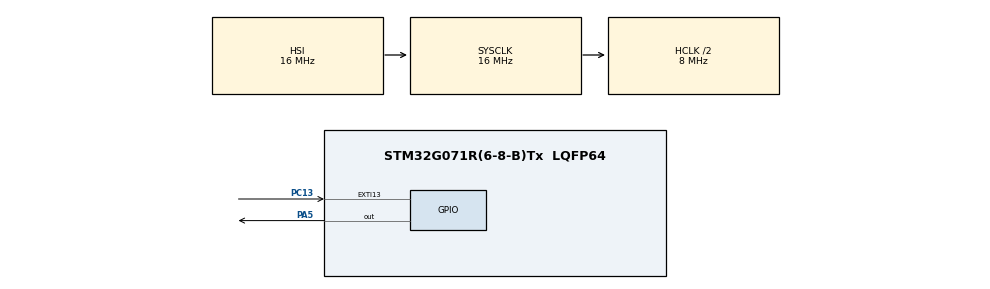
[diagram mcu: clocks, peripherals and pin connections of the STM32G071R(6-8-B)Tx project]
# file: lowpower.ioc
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Mcu.Family=STM32G0
Mcu.Name=STM32G071R(6-8-B)Tx
Mcu.Package=LQFP64
NVIC.EXTI4_15_IRQn=true\:0\:0\:false\:false\:true\:true
NVIC.RTC_TAMP_IRQn=true\:0\:0\:false\:false\:true\:true
PA5.Signal=GPIO_Output
PC13.Signal=GPXTI13
PC14-OSC32_IN\ (PC14).Mode=LSE-External-Oscillator
PC14-OSC32_IN\ (PC14).Signal=RCC_OSC32_IN
PC15-OSC32_OUT\ (PC15).Mode=LSE-External-Oscillator
PC15-OSC32_OUT\ (PC15).Signal=RCC_OSC32_OUT
ProjectManager.HeapSize=0x200
ProjectManager.StackSize=0x400
ProjectManager.TargetToolchain=MDK-ARM V5
RCC.AHBCLKDivider=RCC_SYSCLK_DIV2
RCC.AHBFreq_Value=8000000
RCC.CortexFreq_Value=8000000
RCC.EXTERNAL_CLOCK_VALUE=48000
RCC.HCLKFreq_Value=8000000
RCC.HSE_VALUE=8000000
RCC.HSI_VALUE=16000000
RCC.RTCClockSelection=RCC_RTCCLKSOURCE_LSE
RCC.SYSCLKFreq_VALUE=16000000
RCC.VCOOutputFreq_Value=128000000
RTC.WakeUpCounter-WakeUp=10246
VP_RTC_VS_RTC_Activate.Mode=RTC_Enabled
VP_RTC_VS_RTC_WakeUp_intern.Mode=WakeUp
board=custom

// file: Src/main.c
/* USER CODE BEGIN Header */
/**
  ******************************************************************************
  * @file           : main.c
  * @brief          : Main program body
  ******************************************************************************
  ** This notice applies to any and all portions of this file
  * that are not between comment pairs USER CODE BEGIN and
  * USER CODE END. Other portions of this file, whether
  * inserted by the user or by software development tools
  * are owned by their respective copyright owners.
  *
  * COPYRIGHT(c) 2019 STMicroelectronics
  *
  * Redistribution and use in source and binary forms, with or without modification,
  * are permitted provided that the following conditions are met:
  *   1. Redistributions of source code must retain the above copyright notice,
  *      this list of conditions and the following disclaimer.
  *   2. Redistributions in binary form must reproduce the above copyright notice,
  *      this list of conditions and the following disclaimer in the documentation
  *      and/or other materials provided with the distribution.
  *   3. Neither the name of STMicroelectronics nor the names of its contributors
  *      may be used to endorse or promote products derived from this software
  *      without specific prior written permission.
  *
  * THIS SOFTWARE IS PROVIDED BY THE COPYRIGHT HOLDERS AND CONTRIBUTORS "AS IS"
  * AND ANY EXPRESS OR IMPLIED WARRANTIES, INCLUDING, BUT NOT LIMITED TO, THE
  * IMPLIED WARRANTIES OF MERCHANTABILITY AND FITNESS FOR A PARTICULAR PURPOSE ARE
  * DISCLAIMED. IN NO EVENT SHALL THE COPYRIGHT HOLDER OR CONTRIBUTORS BE LIABLE
  * FOR ANY DIRECT, INDIRECT, INCIDENTAL, SPECIAL, EXEMPLARY, OR CONSEQUENTIAL
  * DAMAGES (INCLUDING, BUT NOT LIMITED TO, PROCUREMENT OF SUBSTITUTE GOODS OR
  * SERVICES; LOSS OF USE, DATA, OR PROFITS; OR BUSINESS INTERRUPTION) HOWEVER
  * CAUSED AND ON ANY THEORY OF LIABILITY, WHETHER IN CONTRACT, STRICT LIABILITY,
  * OR TORT (INCLUDING NEGLIGENCE OR OTHERWISE) ARISING IN ANY WAY OUT OF THE USE
  * OF THIS SOFTWARE, EVEN IF ADVISED OF THE POSSIBILITY OF SUCH DAMAGE.
  *
  ******************************************************************************
  */
/* USER CODE END Header */

#include "main.h"

RTC_HandleTypeDef hrtc;

void SystemClock_Config(void);
static void MX_GPIO_Init(void);
static void MX_RTC_Init(void);

int main(void)
{

  /* MCU Configuration--------------------------------------------------------*/

  /* Reset of all peripherals, Initializes the Flash interface and the Systick. */
  HAL_Init();

  /* Configure the system clock */
  SystemClock_Config();

  /* Initialize all configured peripherals */
  MX_GPIO_Init();
  MX_RTC_Init();

  /* Infinite loop */
  /* USER CODE BEGIN WHILE */
  while (1)
  {
		HAL_GPIO_WritePin(GPIOA, GPIO_PIN_5, GPIO_PIN_SET);
		HAL_Delay(1000);
		HAL_GPIO_WritePin(GPIOA, GPIO_PIN_5, GPIO_PIN_RESET);

		// enter STOP mode
		HAL_PWR_EnterSTOPMode(PWR_LOWPOWERREGULATOR_ON, PWR_STOPENTRY_WFI);

		// reconfigure system clock
		SystemClock_Config();
    /* USER CODE END WHILE */

  }
}

void SystemClock_Config(void)
{
  RCC_OscInitTypeDef RCC_OscInitStruct = {0};
  RCC_ClkInitTypeDef RCC_ClkInitStruct = {0};
  RCC_PeriphCLKInitTypeDef PeriphClkInit = {0};

  /**Configure the main internal regulator output voltage
  */
  HAL_PWREx_ControlVoltageScaling(PWR_REGULATOR_VOLTAGE_SCALE1);
  /**Configure LSE Drive Capability
  */
  __HAL_RCC_LSEDRIVE_CONFIG(RCC_LSEDRIVE_LOW);
  /**Initializes the CPU, AHB and APB busses clocks
  */
  RCC_OscInitStruct.OscillatorType = RCC_OSCILLATORTYPE_HSI|RCC_OSCILLATORTYPE_LSE;
  RCC_OscInitStruct.LSEState = RCC_LSE_ON;
  RCC_OscInitStruct.HSIState = RCC_HSI_ON;
  RCC_OscInitStruct.HSIDiv = RCC_HSI_DIV1;
  RCC_OscInitStruct.HSICalibrationValue = RCC_HSICALIBRATION_DEFAULT;
  RCC_OscInitStruct.PLL.PLLState = RCC_PLL_NONE;
  if (HAL_RCC_OscConfig(&RCC_OscInitStruct) != HAL_OK)
  {
    Error_Handler();
  }
  /**Initializes the CPU, AHB and APB busses clocks
  */
  RCC_ClkInitStruct.ClockType = RCC_CLOCKTYPE_HCLK|RCC_CLOCKTYPE_SYSCLK
                              |RCC_CLOCKTYPE_PCLK1;
  RCC_ClkInitStruct.SYSCLKSource = RCC_SYSCLKSOURCE_HSI;
  RCC_ClkInitStruct.AHBCLKDivider = RCC_SYSCLK_DIV2;
  RCC_ClkInitStruct.APB1CLKDivider = RCC_HCLK_DIV1;

  if (HAL_RCC_ClockConfig(&RCC_ClkInitStruct, FLASH_LATENCY_0) != HAL_OK)
  {
    Error_Handler();
  }
  /**Initializes the peripherals clocks
  */
  PeriphClkInit.PeriphClockSelection = RCC_PERIPHCLK_RTC;
  PeriphClkInit.RTCClockSelection = RCC_RTCCLKSOURCE_LSE;

  if (HAL_RCCEx_PeriphCLKConfig(&PeriphClkInit) != HAL_OK)
  {
    Error_Handler();
  }
}

static void MX_RTC_Init(void)
{

  /**Initialize RTC Only
  */
  hrtc.Instance = RTC;
  hrtc.Init.HourFormat = RTC_HOURFORMAT_24;
  hrtc.Init.AsynchPrediv = 127;
  hrtc.Init.SynchPrediv = 255;
  hrtc.Init.OutPut = RTC_OUTPUT_DISABLE;
  hrtc.Init.OutPutRemap = RTC_OUTPUT_REMAP_NONE;
  hrtc.Init.OutPutPolarity = RTC_OUTPUT_POLARITY_HIGH;
  hrtc.Init.OutPutType = RTC_OUTPUT_TYPE_OPENDRAIN;
  hrtc.Init.OutPutPullUp = RTC_OUTPUT_PULLUP_NONE;
  if (HAL_RTC_Init(&hrtc) != HAL_OK)
  {
    Error_Handler();
  }
  /**Enable the WakeUp
  */
  if (HAL_RTCEx_SetWakeUpTimer_IT(&hrtc, 10246, RTC_WAKEUPCLOCK_RTCCLK_DIV16) != HAL_OK)
  {
    Error_Handler();
  }

}

static void MX_GPIO_Init(void)
{
  GPIO_InitTypeDef GPIO_InitStruct = {0};

  /* GPIO Ports Clock Enable */
  __HAL_RCC_GPIOC_CLK_ENABLE();
  __HAL_RCC_GPIOA_CLK_ENABLE();

  /*Configure GPIO pin Output Level */
  HAL_GPIO_WritePin(GPIOA, GPIO_PIN_5, GPIO_PIN_RESET);

  /*Configure GPIO pin : PC13 */
  GPIO_InitStruct.Pin = GPIO_PIN_13;
  GPIO_InitStruct.Mode = GPIO_MODE_IT_RISING;
  GPIO_InitStruct.Pull = GPIO_NOPULL;
  HAL_GPIO_Init(GPIOC, &GPIO_InitStruct);

  /*Configure GPIO pin : PA5 */
  GPIO_InitStruct.Pin = GPIO_PIN_5;
  GPIO_InitStruct.Mode = GPIO_MODE_OUTPUT_PP;
  GPIO_InitStruct.Pull = GPIO_NOPULL;
  GPIO_InitStruct.Speed = GPIO_SPEED_FREQ_LOW;
  HAL_GPIO_Init(GPIOA, &GPIO_InitStruct);

  /* EXTI interrupt init*/
  HAL_NVIC_SetPriority(EXTI4_15_IRQn, 0, 0);
  HAL_NVIC_EnableIRQ(EXTI4_15_IRQn);

}

void Error_Handler(void)
{
}

/************************ (C) COPYRIGHT STMicroelectronics *****END OF FILE****/
